# nrf54lv10a_enga_application register map
Vendor: Nordic Semiconductor; Series: nrf54l; File version: 1
CPU: CM33 r0p4, little endian, MPU, FPU, 3 interrupt priority bits, 270 interrupts, 4 SAU regions
Registers are 32-bit, read-write, reset 0x0 unless marked. A register's access mark holds for its fields unless they carry their own. Offsets are from the block's base; [hi:lo] are bit positions; lines under a group give offsets from that group; {n}, {i} and the like mark numbered series; 'fields as' and 'values as' point back to an identical list.

## GLOBAL_GRTC_NS — Global Real-time counter 0
Base 0x400E2000
Same registers: GLOBAL_GRTC_S 0x500E2000
{0x0+4i} TASKS_CAPTURE[{i}] (i=0..11) wo — Description collection: Capture the counter value to CC[n] register
  [0] TASKS_CAPTURE — Capture the counter value to CC[n] register
    1=Trigger task
0x60 TASKS_START wo — Start the counter
  [0] TASKS_START
    1=Trigger task
0x64 TASKS_STOP wo — Stop the counter
  [0] TASKS_STOP
    1=Trigger task
0x68 TASKS_CLEAR wo — Clear the counter
  [0] TASKS_CLEAR
    1=Trigger task
0x6C TASKS_PWMSTART wo — Start the PWM
  [0] TASKS_PWMSTART
    1=Trigger task
0x70 TASKS_PWMSTOP wo — Stop the PWM
  [0] TASKS_PWMSTOP
    1=Trigger task
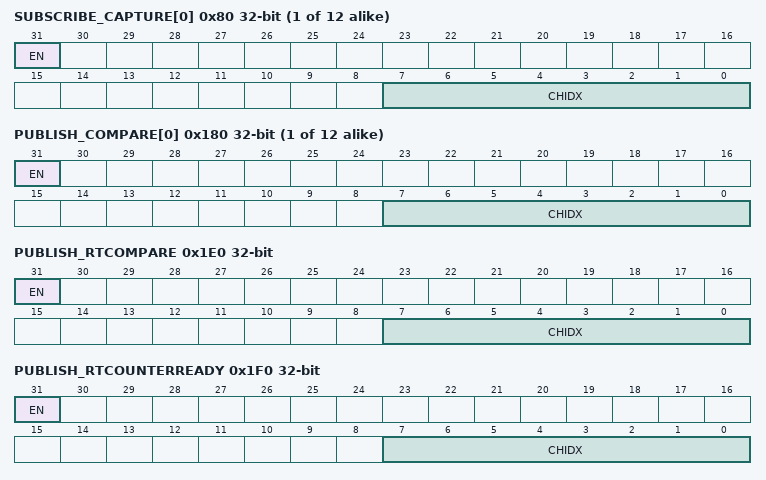
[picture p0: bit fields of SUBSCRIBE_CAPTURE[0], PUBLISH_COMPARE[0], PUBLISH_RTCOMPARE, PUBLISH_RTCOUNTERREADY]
{0x80+4i} SUBSCRIBE_CAPTURE[{i}] (i=0..11) — Description collection: Subscribe configuration for task CAPTURE[n]
  [31] EN
    0=Disabled (Disable subscription); 1=Enabled (Enable subscription)
  [7:0] CHIDX — DPPI channel that task CAPTURE[n] will subscribe to
{0x100+4i} EVENTS_COMPARE[{i}] (i=0..11) — Description collection: Compare event on CC[n] match
  [0] EVENTS_COMPARE — Compare event on CC[n] match
    0=NotGenerated (Event not generated); 1=Generated (Event generated)
0x160 EVENTS_RTCOMPARE — Compare event on RTCOMPARE register match
  [0] EVENTS_RTCOMPARE
    values as EVENTS_COMPARE[0].EVENTS_COMPARE
0x164 EVENTS_RTCOMPARESYNC — The GRTC low frequency timer is synchronized with the SYSCOUNTER
  [0] EVENTS_RTCOMPARESYNC
    values as EVENTS_COMPARE[0].EVENTS_COMPARE
0x168 EVENTS_SYSCOUNTERVALID — The SYSCOUNTER is in active state and value is valid
  [0] EVENTS_SYSCOUNTERVALID
    values as EVENTS_COMPARE[0].EVENTS_COMPARE
0x16C EVENTS_PWMPERIODEND — Event on end of each PWM period
  [0] EVENTS_PWMPERIODEND
    values as EVENTS_COMPARE[0].EVENTS_COMPARE
0x170 EVENTS_RTCOUNTERREADY — Event on STATUS.RTCOUNTER.READY status changed to ready
  [0] EVENTS_RTCOUNTERREADY
    values as EVENTS_COMPARE[0].EVENTS_COMPARE
0x174 EVENTS_PWMREADY — Event on STATUS.PWM.READY status changed to ready
  [0] EVENTS_PWMREADY
    values as EVENTS_COMPARE[0].EVENTS_COMPARE
0x178 EVENTS_CLKOUTREADY — Event on STATUS.CLKOUT.READY status changed to ready
  [0] EVENTS_CLKOUTREADY
    values as EVENTS_COMPARE[0].EVENTS_COMPARE
{0x180+4i} PUBLISH_COMPARE[{i}] (i=0..11) — Description collection: Publish configuration for event COMPARE[n]
  [31] EN
    0=Disabled (Disable publishing); 1=Enabled (Enable publishing)
  [7:0] CHIDX — DPPI channel that event COMPARE[n] will publish to
0x1E0 PUBLISH_RTCOMPARE — Publish configuration for event RTCOMPARE
  [31] EN
    values as PUBLISH_COMPARE[0].EN
  [7:0] CHIDX — DPPI channel that event RTCOMPARE will publish to
0x1F0 PUBLISH_RTCOUNTERREADY — Publish configuration for event RTCOUNTERREADY
  [31] EN
    values as PUBLISH_COMPARE[0].EN
  [7:0] CHIDX — DPPI channel that event RTCOUNTERREADY will publish to
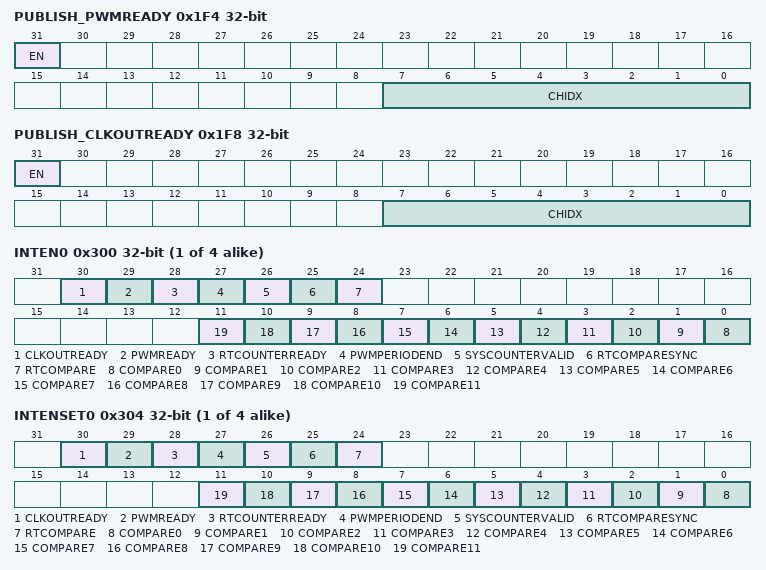
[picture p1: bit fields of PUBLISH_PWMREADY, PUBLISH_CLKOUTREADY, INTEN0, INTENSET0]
0x1F4 PUBLISH_PWMREADY — Publish configuration for event PWMREADY
  [31] EN
    values as PUBLISH_COMPARE[0].EN
  [7:0] CHIDX — DPPI channel that event PWMREADY will publish to
0x1F8 PUBLISH_CLKOUTREADY — Publish configuration for event CLKOUTREADY
  [31] EN
    values as PUBLISH_COMPARE[0].EN
  [7:0] CHIDX — DPPI channel that event CLKOUTREADY will publish to
0x200 SHORTS — Shortcuts between local events and tasks
  [0] RTCOMPARE_CLEAR — Shortcut between event RTCOMPARE and task CLEAR
    0=Disabled (Disable shortcut); 1=Enabled (Enable shortcut)
{0x300+0x10*i} INTEN{i} (i=0..3) — Enable or disable interrupt
  [all] fields
    0=Disabled; 1=Enabled
  [30] CLKOUTREADY — Enable or disable interrupt for event CLKOUTREADY
  [29] PWMREADY — Enable or disable interrupt for event PWMREADY
  [28] RTCOUNTERREADY — Enable or disable interrupt for event RTCOUNTERREADY
  [27] PWMPERIODEND — Enable or disable interrupt for event PWMPERIODEND
  [26] SYSCOUNTERVALID — Enable or disable interrupt for event SYSCOUNTERVALID
  [25] RTCOMPARESYNC — Enable or disable interrupt for event RTCOMPARESYNC
  [24] RTCOMPARE — Enable or disable interrupt for event RTCOMPARE
  [n] COMPARE{n} (n=0..11) — Enable or disable interrupt for event COMPARE[{n}]
{0x304+0x10*i} INTENSET{i} (i=0..3) — Enable interrupt
  [all] fields
    on read: 0=Disabled (Read: Disabled); 1=Enabled (Read: Enabled) | on write: 1=Set (Enable)
  [30] CLKOUTREADY — Write '1' to enable interrupt for event CLKOUTREADY
  [29] PWMREADY — Write '1' to enable interrupt for event PWMREADY
  [28] RTCOUNTERREADY — Write '1' to enable interrupt for event RTCOUNTERREADY
  [27] PWMPERIODEND — Write '1' to enable interrupt for event PWMPERIODEND
  [26] SYSCOUNTERVALID — Write '1' to enable interrupt for event SYSCOUNTERVALID
  [25] RTCOMPARESYNC — Write '1' to enable interrupt for event RTCOMPARESYNC
  [24] RTCOMPARE — Write '1' to enable interrupt for event RTCOMPARE
  [n] COMPARE{n} (n=0..11) — Write '1' to enable interrupt for event COMPARE[{n}]
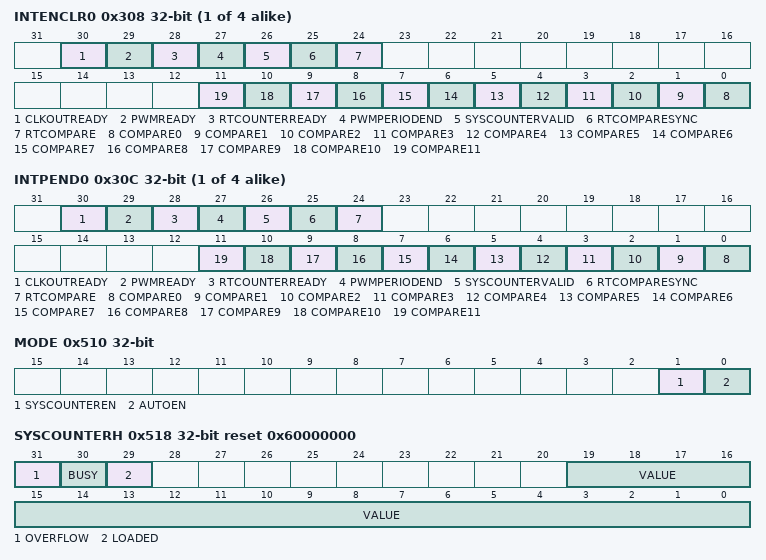
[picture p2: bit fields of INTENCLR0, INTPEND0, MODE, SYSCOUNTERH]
{0x308+0x10*i} INTENCLR{i} (i=0..3) — Disable interrupt
  [all] fields
    on read: 0=Disabled (Read: Disabled); 1=Enabled (Read: Enabled) | on write: 1=Clear (Disable)
  [30] CLKOUTREADY — Write '1' to disable interrupt for event CLKOUTREADY
  [29] PWMREADY — Write '1' to disable interrupt for event PWMREADY
  [28] RTCOUNTERREADY — Write '1' to disable interrupt for event RTCOUNTERREADY
  [27] PWMPERIODEND — Write '1' to disable interrupt for event PWMPERIODEND
  [26] SYSCOUNTERVALID — Write '1' to disable interrupt for event SYSCOUNTERVALID
  [25] RTCOMPARESYNC — Write '1' to disable interrupt for event RTCOMPARESYNC
  [24] RTCOMPARE — Write '1' to disable interrupt for event RTCOMPARE
  [n] COMPARE{n} (n=0..11) — Write '1' to disable interrupt for event COMPARE[{n}]
{0x30C+0x10*i} INTPEND{i} ro (i=0..3) — Pending interrupts
  [all] fields
    on read: 0=NotPending (Read: Not pending); 1=Pending (Read: Pending)
  [30] CLKOUTREADY — Read pending status of interrupt for event CLKOUTREADY
  [29] PWMREADY — Read pending status of interrupt for event PWMREADY
  [28] RTCOUNTERREADY — Read pending status of interrupt for event RTCOUNTERREADY
  [27] PWMPERIODEND — Read pending status of interrupt for event PWMPERIODEND
  [26] SYSCOUNTERVALID — Read pending status of interrupt for event SYSCOUNTERVALID
  [25] RTCOMPARESYNC — Read pending status of interrupt for event RTCOMPARESYNC
  [24] RTCOMPARE — Read pending status of interrupt for event RTCOMPARE
  [n] COMPARE{n} (n=0..11) — Read pending status of interrupt for event COMPARE[{n}]
0x400 EVTEN — Enable or disable event routing
  [27] PWMPERIODEND — Enable or disable event routing for event PWMPERIODEND
    0=Disabled; 1=Enabled
0x404 EVTENSET — Enable event routing
  [27] PWMPERIODEND — Write '1' to enable event routing for event PWMPERIODEND
    values as the fields of INTENSET0
0x408 EVTENCLR — Disable event routing
  [27] PWMPERIODEND — Write '1' to disable event routing for event PWMPERIODEND
    values as the fields of INTENCLR0
0x500 RTCOUNTERL ro — The lower 32-bits of the RTCOUNTER counter.
  [31:0] VALUE — The lower 32-bits of the current counter value.
0x504 RTCOUNTERH ro — The most significant bits of the RTCOUNTER counter.
  [14:0] VALUE — The most significant bits of the last latched counter.
0x510 MODE — Counter mode selection
  [1] SYSCOUNTEREN — Enable the SYSCOUNTER
    0=Disabled (SYSCOUNTER disabled); 1=Enabled (SYSCOUNTER enabled)
  [0] AUTOEN — Automatic enable to keep the SYSCOUNTER active.
    0=Default configuration to keep the SYSCOUNTER active; 1=CpuActive (In addition to the above mode, any local CPU that is not sleeping keep the SYSCOUNTER active.)
0x514 SYSCOUNTERL — The lower 32-bits of the SYSCOUNTER
  [31:0] VALUE — The lower 32-bits of the SYSCOUNTER value.
0x518 SYSCOUNTERH reset 0x60000000 — The higher 20-bits of the SYSCOUNTER
  [31] OVERFLOW ro — The SYSCOUNTERL overflow indication after reading it.
    0=NoOverflow (SYSCOUNTERL is not overflown); 1=Overflow (SYSCOUNTERL overflown)
  [30] BUSY ro — SYSCOUNTER busy status
    0=Ready (SYSCOUNTER is ready for read); 1=Busy (SYSCOUNTER is busy, so not ready for read (value returned in the field SYSCOUNTERH.VALUE is not valid))
  [29] LOADED — SYSCOUNTER loaded status
    0=NotLoaded (SYSCOUNTER is not loaded); 1=Loaded (SYSCOUNTER is loaded)
  [19:0] VALUE — The higher 20-bits of the SYSCOUNTER value.
{0x520+0x10*i} CC[{i}] (i=0..11) group — Unspecified
  0x00 CCL — Description cluster: The lower 32-bits of Capture/Compare register CC[n]
    [31:0] CCL — Capture/Compare low value in 1 us
  0x04 CCH — Description cluster: The higher 32-bits of Capture/Compare register CC[n]
    [19:0] CCH — Capture/Compare high value in 1 us
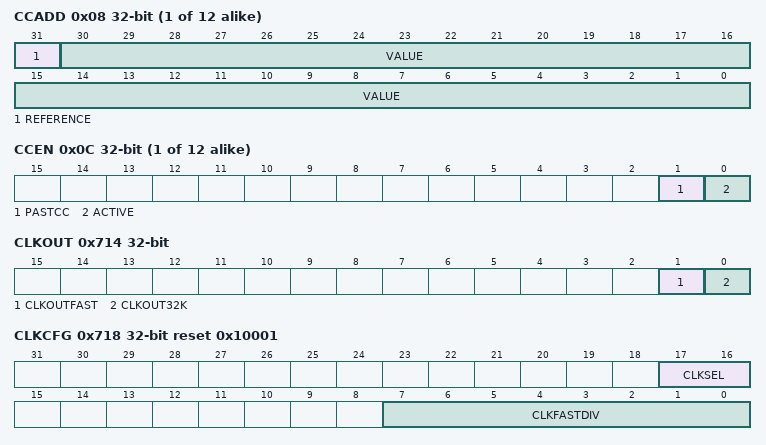
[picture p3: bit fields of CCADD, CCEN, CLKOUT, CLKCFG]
  0x08 CCADD — Description cluster: Count to add to CC[n] when this register is written.
    [31] REFERENCE — Configure the Capture/Compare register
      0=SYSCOUNTER (Adds SYSCOUNTER value.); 1=CC (Adds CC value.)
    [30:0] VALUE — Count to add to CC[n]
  0x0C CCEN — Description cluster: Configure Capture/Compare register CC[n]
    [1] PASTCC — Status of event EVENTS_COMPARE[n] caused by the configured CC value is in past
      0=Inactive; 1=Active
    [0] ACTIVE — Configure the Capture/Compare register
      0=Disable (Capture/Compare register CC[n] Disabled.); 1=Enable (Capture/Compare register CC[n] enabled.)
0x6A0 KEEPRUNNING — Deprecated register - Request to keep the SYSCOUNTER in the active state and prevent going to sleep
  [all] fields
    0=NotActive (Allow SYSCOUNTER to go to sleep); 1=Active (Keep SYSCOUNTER active)
  [n] DOMAIN_{n} (n=0..15) — Deprecated field - Request from the Domain [{n}]
  [n] REQUEST_{n} (n=0..3) — Request from index [{n}]
0x6A4 TIMEOUT — Timeout after all CPUs gone into sleep state to stop the SYSCOUNTER
  [15:0] VALUE — Number of 32Ki cycles
0x6A8 INTERVAL — Count to add to CC[0] when the event EVENTS_COMPARE[0] triggers.
  [15:0] VALUE — Count to add to CC[0]
0x6AC WAKETIME reset 0x1 — GRTC wake up time.
  [7:0] VALUE — Number of LFCLK clock cycles to wake up before the next scheduled EVENTS_COMPARE event
0x6B0 STATUS group — Unspecified
  0x00 LFTIMER reset 0x1 — Low frequency timer status.
    [0] READY ro — Low frequency timer is ready or busy.
      0=Busy; 1=Ready
  0x00 RTCOUNTER reset 0x1 (alternate view of LFTIMER) — RTCOUNTER status.
    [0] READY ro — RTCOUNTER is ready or busy.
      0=Busy; 1=Ready
  0x04 PWM reset 0x1 — PWM status.
    [0] READY ro — PWM is ready or busy.
      0=Busy; 1=Ready
  0x08 CLKOUT reset 0x1 — CLKOUT configuration status.
    [0] READY ro — CLKOUT is ready or busy.
      0=Busy; 1=Ready
0x700 RTCOMPAREL — The lower 32-bits of the RTCOMPARE register.
  [31:0] VALUE — The lower 32-bits of the compare value.
0x704 RTCOMPAREH — The most significant bits of the RTCOMPARE register.
  [14:0] VALUE — The most significant bits of the compare value.
0x708 RTCOMPARESYNCL — The lower 32-bits of the RTCOMPARESYNC register.
  [31:0] VALUE — The lower 32-bits of the compare value.
0x70C RTCOMPARESYNCH — The most significant bits of the RTCOMPARESYNC register.
  [14:0] VALUE — The most significant bits of the compare value.
0x710 PWMCONFIG — PWM configuration.
  [7:0] COMPAREVALUE — The PWM compare value
0x714 CLKOUT — Configuration of clock output
  [1] CLKOUTFAST — Enable fast clock output on pin
    0=Disabled; 1=Enabled
  [0] CLKOUT32K — Enable 32Ki clock output on pin
    0=Disabled; 1=Enabled
0x718 CLKCFG reset 0x10001 — Clock Configuration
  [17:16] CLKSEL wo — GRTC LFCLK clock source selection
    0=LFXO (GRTC LFCLK clock source is LFXO); 1=SystemLFCLK (GRTC LFCLK clock source is system LFCLK); 2=LFLPRC (GRTC LFCLK clock source is LFLPRC)
  [7:0] CLKFASTDIV — Fast clock divisor value of clock output
{0x720+0x10*i} SYSCOUNTER[{i}] (i=0..3) group — Unspecified
  0x00 SYSCOUNTERL ro — Description cluster: The lower 32-bits of the SYSCOUNTER for index [n]
    [31:0] VALUE — The lower 32-bits of the SYSCOUNTER value.
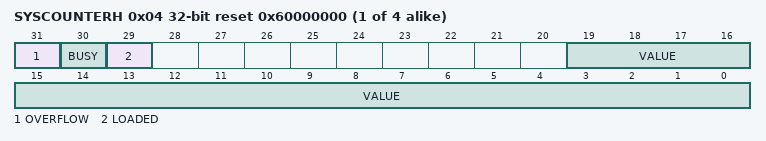
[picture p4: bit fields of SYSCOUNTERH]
  0x04 SYSCOUNTERH ro reset 0x60000000 — Description cluster: The higher 20-bits of the SYSCOUNTER for index [n]
    [31] OVERFLOW — The SYSCOUNTERL overflow indication after reading it.
      values as SYSCOUNTERH.OVERFLOW
    [30] BUSY — SYSCOUNTER busy status
      0=Ready (SYSCOUNTER is ready for read); 1=Busy (SYSCOUNTER is busy, so not ready for read (value returned in the VALUE field of this register is not valid))
    [29] LOADED — SYSCOUNTER loaded status
      values as SYSCOUNTERH.LOADED
    [19:0] VALUE — The higher 20-bits of the SYSCOUNTER value.
  0x08 ACTIVE — Description cluster: Request to keep the SYSCOUNTER in the active state and prevent going to sleep for index [n]
    [0] ACTIVE — Keep SYSCOUNTER in active state
      values as the fields of KEEPRUNNING
